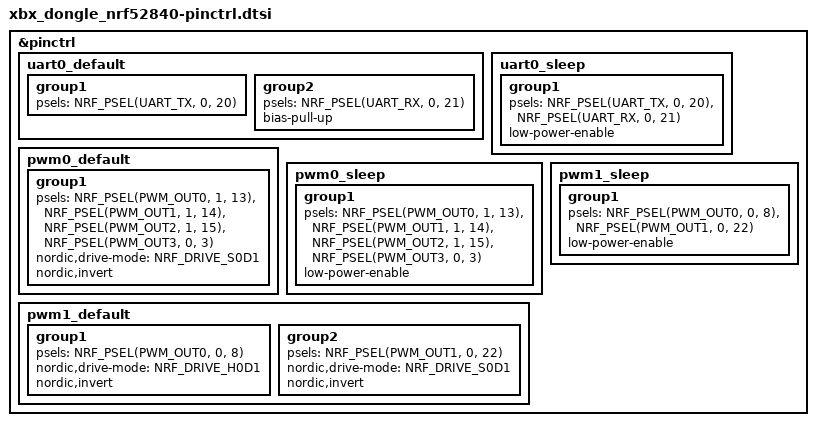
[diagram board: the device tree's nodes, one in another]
&pinctrl {
	/* J3 debug UART (JST-SH, Raspberry Pi pinout) */
	uart0_default: uart0_default {
		group1 {
			psels = <NRF_PSEL(UART_TX, 0, 20)>;
		};

		group2 {
			psels = <NRF_PSEL(UART_RX, 0, 21)>;
			bias-pull-up;
		};
	};

	uart0_sleep: uart0_sleep {
		group1 {
			psels = <NRF_PSEL(UART_TX, 0, 20)>,
				<NRF_PSEL(UART_RX, 0, 21)>;
			low-power-enable;
		};
	};

	/*
	 * LEDs, open-drain (disconnect '1'), idle high = off. P0.22 (power
	 * LED): with JP1 1–2 also bridged it's shorted to GND, so it must
	 * never drive high.
	 */
	pwm0_default: pwm0_default {
		group1 {
			psels = <NRF_PSEL(PWM_OUT0, 1, 13)>, /* P1 */
				<NRF_PSEL(PWM_OUT1, 1, 14)>, /* P2 */
				<NRF_PSEL(PWM_OUT2, 1, 15)>, /* P3 */
				<NRF_PSEL(PWM_OUT3, 0, 3)>;  /* P4 */
			nordic,drive-mode = <NRF_DRIVE_S0D1>;
			nordic,invert;
		};
	};

	pwm0_sleep: pwm0_sleep {
		group1 {
			psels = <NRF_PSEL(PWM_OUT0, 1, 13)>,
				<NRF_PSEL(PWM_OUT1, 1, 14)>,
				<NRF_PSEL(PWM_OUT2, 1, 15)>,
				<NRF_PSEL(PWM_OUT3, 0, 3)>;
			low-power-enable;
		};
	};

	pwm1_default: pwm1_default {
		/* pair LED, 180 Ω: high drive */
		group1 {
			psels = <NRF_PSEL(PWM_OUT0, 0, 8)>;
			nordic,drive-mode = <NRF_DRIVE_H0D1>;
			nordic,invert;
		};

		/* power LED */
		group2 {
			psels = <NRF_PSEL(PWM_OUT1, 0, 22)>;
			nordic,drive-mode = <NRF_DRIVE_S0D1>;
			nordic,invert;
		};
	};

	pwm1_sleep: pwm1_sleep {
		group1 {
			psels = <NRF_PSEL(PWM_OUT0, 0, 8)>,
				<NRF_PSEL(PWM_OUT1, 0, 22)>;
			low-power-enable;
		};
	};
};
